# Cortex-M0Plus register map
File version: 1.0
Cortex-M0+ Core Peripherals
CPU: Cortex-M0+ r0p0, little endian, no MPU, no FPU, 2 interrupt priority bits
Registers are 32-bit, read-write, no defined reset value unless marked. A register's access mark holds for its fields unless they carry their own. Offsets are from the block's base; lines under a group give offsets from that group; [hi:lo] are bit positions; {n}, {i} and the like mark numbered series; 'fields as' and 'values as' point back to an identical list; <NAME> marks a mode.

## Memory map
0xE000E010 SysTick — System Timer
0xE000E100 NVIC — Nested Vectored Interrupt Controller
0xE000ED00 SCB — System Control Block

## SCB — System Control Block
Base 0xE000ED00
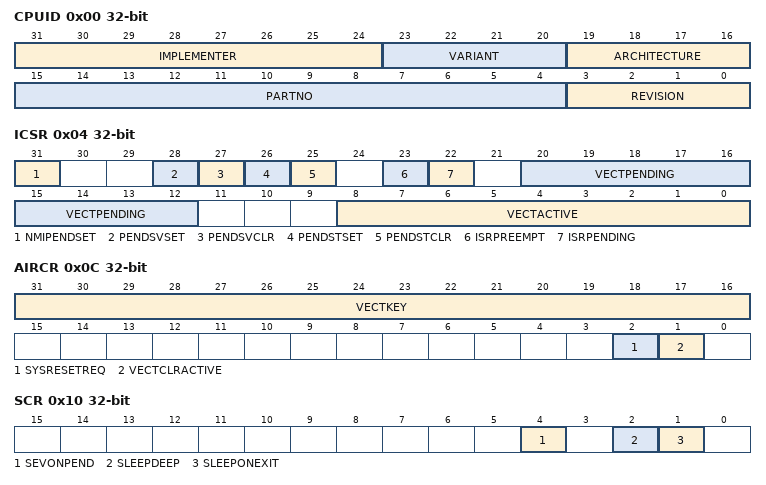
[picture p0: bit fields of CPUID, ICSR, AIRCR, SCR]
0x00 CPUID ro — CPUID Base Register
  [31:24] IMPLEMENTER — Implementer code
  [23:20] VARIANT — Variant number
  [19:16] ARCHITECTURE — Architecture code
  [15:4] PARTNO — Part number
  [3:0] REVISION — Revision number
0x04 ICSR — Interrupt Control and State Register
  [31] NMIPENDSET — NMI set-pending bit
  [28] PENDSVSET — PendSV set-pending bit
  [27] PENDSVCLR — PendSV clear-pending bit
  [26] PENDSTSET — SysTick set-pending bit
  [25] PENDSTCLR — SysTick clear-pending bit
  [23] ISRPREEMPT — ISR preempt status
  [22] ISRPENDING — Interrupt pending flag
  [20:12] VECTPENDING — Pending ISR number
  [8:0] VECTACTIVE — Active ISR number
0x08 VTOR — Vector Table Offset Register
  [31:8] TBLOFF — Vector table base offset field
0x0C AIRCR — Application Interrupt and Reset Control Register
  [31:16] VECTKEY — Register key
  [2] SYSRESETREQ — System reset request
  [1] VECTCLRACTIVE — Clear active vector flag
0x10 SCR — System Control Register
  [4] SEVONPEND — Send Event on Pending
  [2] SLEEPDEEP — Deep sleep enable
  [1] SLEEPONEXIT — Sleep on ISR exit
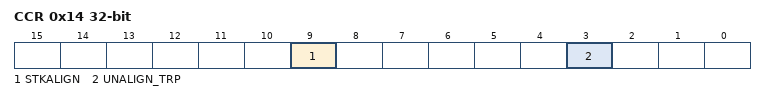
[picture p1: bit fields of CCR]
0x14 CCR — Configuration Control Register
  [9] STKALIGN — Stack alignment on exception entry
  [3] UNALIGN_TRP — Unaligned access traps
{0x18+i} SHP[{i}] (i=4..11) 8-bit — System Handlers Priority Registers
  [7:6] PRI — Priority Bits
0x24 SHCSR — System Handler Control and State Register
  [15] SVCALLPENDED — SVCall pending status

## NVIC — Nested Vectored Interrupt Controller
Base 0xE000E100
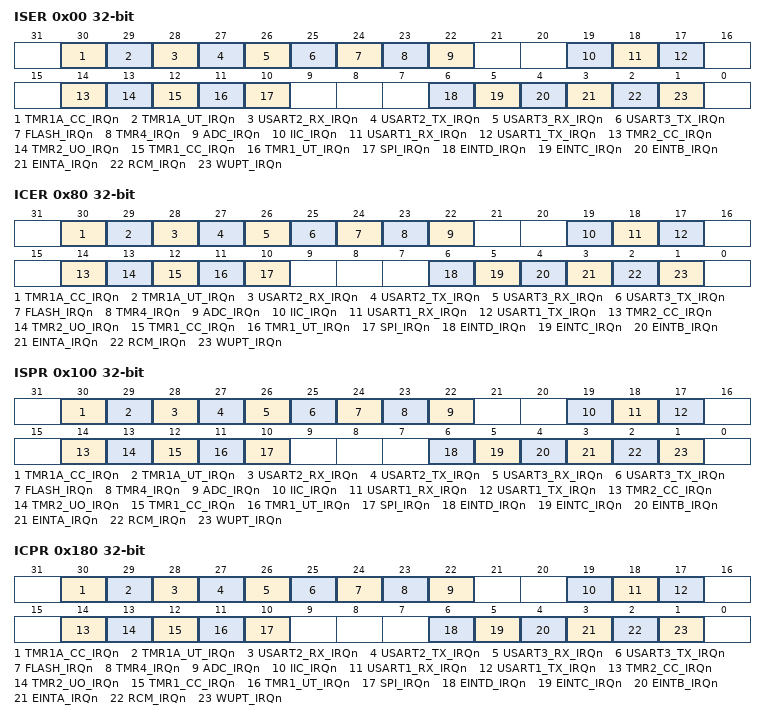
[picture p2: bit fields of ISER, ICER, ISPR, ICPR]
0x00 ISER — Interrupt Set Enable Register
  [30] TMR1A_CC_IRQn — TIMER1A capture/compare interrupt
  [29] TMR1A_UT_IRQn — TIMER1A update/overflow/underflow/trigger/break interrupt
  [28] USART2_RX_IRQn — USART2 RX interrupt
  [27] USART2_TX_IRQn — USART2 TX interrupt
  [26] USART3_RX_IRQn — USART3 RX interrupt
  [25] USART3_TX_IRQn — USART3 TX interrupt
  [24] FLASH_IRQn — Flash interrupt
  [23] TMR4_IRQn — TIMER4 interrupt
  [22] ADC_IRQn — ADC interrupt
  [19] IIC_IRQn — I2C Interrupt
  [18] USART1_RX_IRQn — USART1 RX interrupt
  [17] USART1_TX_IRQn — USART1 TX interrupt
  [14] TMR2_CC_IRQn — TIMER2 capture/compare interrupt
  [13] TMR2_UO_IRQn — TIMER2 update/overflow interrupt
  [12] TMR1_CC_IRQn — TIMER1 capture/compare interrupt
  [11] TMR1_UT_IRQn — TIMER1 update/overflow/underflow/trigger/break interrupt
  [10] SPI_IRQn — SPI Interrupt
  [6] EINTD_IRQn — Port D external interrupts
  [5] EINTC_IRQn — Port C external interrupts
  [4] EINTB_IRQn — Port B external interrupts
  [3] EINTA_IRQn — Port A external interrupts
  [2] RCM_IRQn — Clock controller interrupt
  [1] WUPT_IRQn — Wakeup timer
0x80 ICER — Interrupt Clear Enable Register
  fields as ISER
0x100 ISPR — Interrupt Set Pending Register
  fields as ISER
0x180 ICPR — Interrupt Clear Pending Register
  fields as ISER
{0x300+i} IP[{i}] (i=0..31) 8-bit — Interrupt Priority Register
  [7:6] PRI — Priority Bits

## SysTick — System Timer
Base 0xE000E010
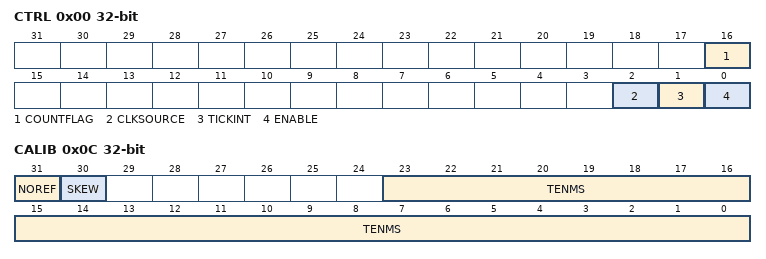
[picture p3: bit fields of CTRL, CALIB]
0x00 CTRL — SysTick Control and Status Register
  [16] COUNTFLAG
  [2] CLKSOURCE — Clock Source
  [1] TICKINT — Tick Interrupt
  [0] ENABLE — Counter Enable
0x04 LOAD — SysTick Reload Value Register
0x08 VAL — SysTick Current Value Register
0x0C CALIB ro — SysTick Calibration Register
  [31] NOREF — No reference clock
  [30] SKEW — Skewed clock
  [23:0] TENMS — Ten milliseconds value
